# nrf54h20_engb_sysctrl register map
Vendor: Nordic Semiconductor; Series: nRF54h; File version: 1
Registers are 32-bit, read-write, reset 0x0 unless marked. A register's access mark holds for its fields unless they carry their own. Offsets are from the block's base; [hi:lo] are bit positions; lines under a group give offsets from that group; {n}, {i} and the like mark numbered series; 'fields as' and 'values as' point back to an identical list.

## CLKMON — CLKMON peripheral
Base 0x5F956000
0x100 EVENTS_LFXOERROR — LFXO error detected
  [0] EVENTS_LFXOERROR
    0=NotGenerated (Event not generated); 1=Generated (Event generated)
0x300 INTEN — Enable or disable interrupt
  [0] LFXOERROR — Enable or disable interrupt for event LFXOERROR
    0=Disabled; 1=Enabled
0x304 INTENSET — Enable interrupt
  [0] LFXOERROR — Write '1' to enable interrupt for event LFXOERROR
    on read: 0=Disabled (Read: Disabled); 1=Enabled (Read: Enabled) | on write: 1=Set (Enable)
0x308 INTENCLR — Disable interrupt
  [0] LFXOERROR — Write '1' to disable interrupt for event LFXOERROR
    on read: 0=Disabled (Read: Disabled); 1=Enabled (Read: Enabled) | on write: 1=Clear (Disable)
0x30C INTPEND ro — Pending interrupts
  [0] LFXOERROR — Read pending status of interrupt for event LFXOERROR
    on read: 0=NotPending (Read: Not pending); 1=Pending (Read: Pending)
0x400 STATUS ro — Clock monitor status
  [0] ERROR — LFXO error status
    0=NotDetected (No error detected); 1=Detected (Error detected)
0x404 ENABLE — Enable the clock monitor
  [0] EN — Enable
    0=Disabled (Clock monitor disabled); 1=Enabled (Clock monitor enabled)

## VREGSU — VREGSU peripheral
Base 0x5F966000
0x480 PWRUPCTRL — Power up control
  [0] CTRL
    0=PowerDown; 1=PowerUp
0x600 DFT group — Unspecified
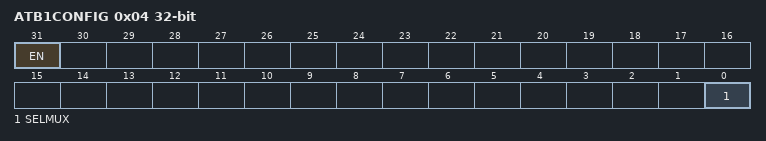
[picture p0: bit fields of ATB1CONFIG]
  0x04 ATB1CONFIG — Analog Test Bus 1 (ATB1) configuration
    [31] EN — Enable the analog test bus
      0=Disabled (Analog test bus is disabled); 1=Enabled (Analog test bus is enabled)
    [0] SELMUX — Select multiplexer for ATB1
      0=Spare0 (HiZ. For future use); 1=VFB1V2 (VDD_AO_1V8 scaled by 2/3)

## OSCRFR — OSCRFR peripheral
Base 0x5F96B000
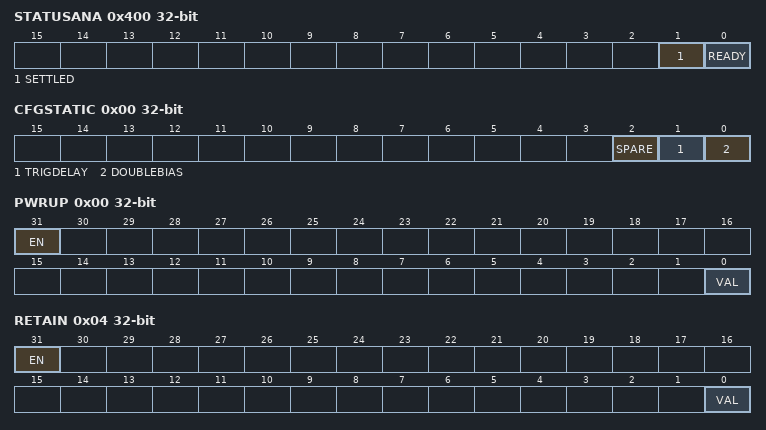
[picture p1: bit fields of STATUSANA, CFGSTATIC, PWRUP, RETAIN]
0x400 STATUSANA ro — Status of analog module output signals
  [1] SETTLED — Current value of the SETTLED signal from the analog module
  [0] READY — Current value of the READY signal from the analog module
0x410 CONFIG group — Unspecified
  0x00 CFGSTATIC — OSCRFR static CFG configuration
    [2] SPARE
    [1] TRIGDELAY — Increase TRIG signal delay
      0=Disabled; 1=Enabled
    [0] DOUBLEBIAS — Enable double bias
      0=Disabled; 1=Enabled
0x440 TRIM group — Unspecified
  0x00 OSC — Oscillation period trimming
    [2:0] VAL — Oscillation period trimming value
      0=Normal trim value; 1=Oscillation period increases by 35 percent; 2=Oscillation period increases by 154 percent; 3=Oscillation period increases by 670 percent; 4=ValNeg54 (Oscillation period decreases by 54 percent); 5=ValNeg49 (Oscillation period decreases by 49 percent); 6=ValNeg37 (Oscillation period decreases by 37 percent); 7=ValNeg26 (Oscillation period decreases by 26 percent)
  0x04 IBPSR — IBPSR current trimming
    [3:0] VAL — IBPSR current and VREF voltage trimming value
0x480 MIRROR reset 0x1 — Enable LOCK for mirrored registers
  [0] LOCK — Lock for mirrored registers
    0=Disabled (Lock disabled); 1=Enabled (Lock enabled)
0x484 MODE — Oscillator mode
  [0] MODE
    0=Normal mode - Use internal oscillator; 1=Bypass mode - Use OSC_RFR_DIG_AO_0V8 signal
0x500 OVERRIDE group — Unspecified
  0x00 PWRUP — Override the PWRUP signal to the analog module
    [31] EN — Enable the override
      0=Disabled (Override is disabled); 1=Enabled (Override is enabled)
    [0] VAL — Override value for the signal
  0x04 RETAIN — Override the RETAIN signal to the analog module
    fields as OVERRIDE.PWRUP
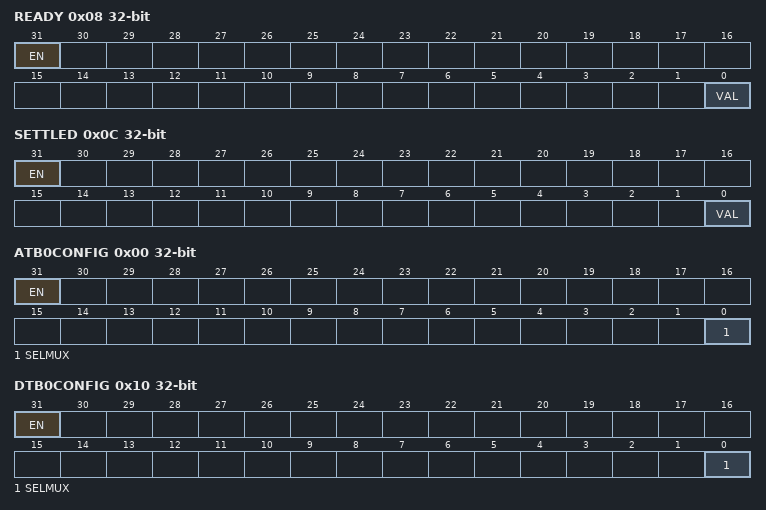
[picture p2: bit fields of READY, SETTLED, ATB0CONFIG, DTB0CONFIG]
  0x08 READY — Override the READY signal from the analog module
    [31] EN — Enable the override
      values as OVERRIDE.PWRUP.EN
    [0] VAL — Current value of the signal
  0x0C SETTLED — Override the SETTLED signal from the analog module
    fields as OVERRIDE.READY
0x600 DFT group — Unspecified
  0x00 ATB0CONFIG — Analog Test Bus 0 (ATB0) configuration
    [31] EN — Enable the analog test bus
      0=Disabled (Analog test bus is disabled); 1=Enabled (Analog test bus is enabled)
    [0] SELMUX — Select multiplexer for ATB0
      0=IBPSR4U (IBPSR_4U signal selected); 1=Spare (None selected)
  0x10 DTB0CONFIG — Digital Test Bus 0 (DTB0) configuration
    [31] EN — Enable the digital test bus
      0=Disabled (Digital test bus is disabled); 1=Enabled (Digital test bus is enabled)
    [0] SELMUX — Select multiplexer for DTB0
      0=READY (READY signal selected); 1=OSC (OSC_RFR_ANA_AO_0V8 signal selected)
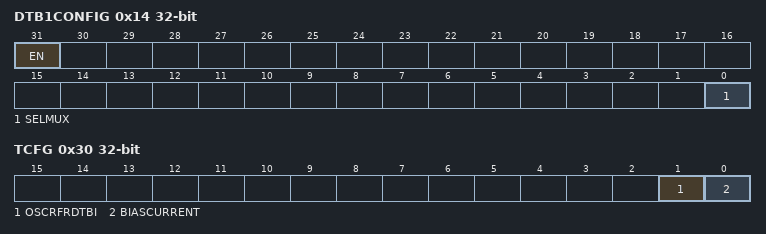
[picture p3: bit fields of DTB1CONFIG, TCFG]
  0x14 DTB1CONFIG — Digital Test Bus 1 (DTB1) configuration
    [31] EN — Enable the digital test bus
      values as DFT.DTB0CONFIG.EN
    [0] SELMUX — Select multiplexer for DTB1
      0=SETTLED (SETTLED signal selected); 1=OSC (OSC_RFR_ANA_AO_0V8 signal selected)
  0x1C DTB3CONFIG — Digital Test Bus 3 (DTB3) configuration
    [27] PWRUPDELTEST — Enable the PWRUP delay test circuit
      0=Disabled (PWRUP delay test circuit is disabled); 1=Enabled (PWRUP delay test circuit is enabled)
  0x30 TCFG — Test mode configuration
    [1] OSCRFRDTBI — Use DTBI input as refresh clock when in bypass mode
      0=Disabled; 1=Enabled
    [0] BIASCURRENT — Enable continuous mode for measuring bias current over ATB
      0=Disabled; 1=Enabled

## VDETIO — VDETIO peripheral
Base 0x5F974000
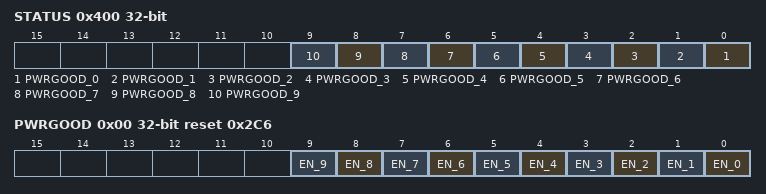
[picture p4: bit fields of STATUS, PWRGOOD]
0x400 STATUS ro — Voltage detector status
  [all] fields
    0=AboveThr (Power good detector detected voltage above threshold level); 1=BelowThr (Power good detector detected voltage below threshold level)
  [n] PWRGOOD_{n} (n=0..9) — Power good detector status for port [{n}]
0x410 CONFIG group — Unspecified
  0x00 PWRGOOD reset 0x2C6 — Power good detector configuration
    [all] fields
      0=Disabled (IO voltage detector is disabled); 1=Enabled (IO voltage detector is enabled)
    [n] EN_{n} (n=0..9) — Enable the power good detector for port [{n}]
